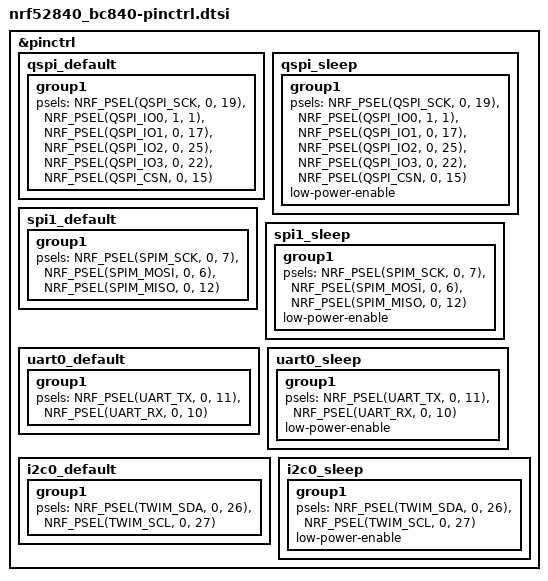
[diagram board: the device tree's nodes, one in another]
/*
 * Copyright (c) 2024 Nordic Semiconductor
 * SPDX-License-Identifier: Apache-2.0
 */

&pinctrl {
	/* QSPI pins for mx25l51245gz2i-08g (64MB) */
	qspi_default: qspi_default {
		group1 {
			psels = <NRF_PSEL(QSPI_SCK, 0, 19)>,
				<NRF_PSEL(QSPI_IO0, 1, 1)>,
				<NRF_PSEL(QSPI_IO1, 0, 17)>,
				<NRF_PSEL(QSPI_IO2, 0, 25)>,
				<NRF_PSEL(QSPI_IO3, 0, 22)>,
				<NRF_PSEL(QSPI_CSN, 0, 15)>;
		};
	};

	qspi_sleep: qspi_sleep {
		group1 {
			psels = <NRF_PSEL(QSPI_SCK, 0, 19)>,
				<NRF_PSEL(QSPI_IO0, 1, 1)>,
				<NRF_PSEL(QSPI_IO1, 0, 17)>,
				<NRF_PSEL(QSPI_IO2, 0, 25)>,
				<NRF_PSEL(QSPI_IO3, 0, 22)>,
				<NRF_PSEL(QSPI_CSN, 0, 15)>;
			low-power-enable;
		};
	};

	/* SPIFX pins for mx25l12845gz2i-08g (16MB) - also QSPI mode */
	/* Note: nRF52840 has only one hardware QSPI peripheral, so we use SPI in quad mode */
	spi1_default: spi1_default {
		group1 {
			psels = <NRF_PSEL(SPIM_SCK, 0, 7)>,
				<NRF_PSEL(SPIM_MOSI, 0, 6)>,
				<NRF_PSEL(SPIM_MISO, 0, 12)>;
		};
	};

	spi1_sleep: spi1_sleep {
		group1 {
			psels = <NRF_PSEL(SPIM_SCK, 0, 7)>,
				<NRF_PSEL(SPIM_MOSI, 0, 6)>,
				<NRF_PSEL(SPIM_MISO, 0, 12)>;
			low-power-enable;
		};
	};

	uart0_default: uart0_default {
		group1 {
			psels = <NRF_PSEL(UART_TX, 0, 11)>,
				<NRF_PSEL(UART_RX, 0, 10)>;
		};
	};

	uart0_sleep: uart0_sleep {
		group1 {
			psels = <NRF_PSEL(UART_TX, 0, 11)>,
				<NRF_PSEL(UART_RX, 0, 10)>;
			low-power-enable;
		};
	};

	i2c0_default: i2c0_default {
		group1 {
			psels = <NRF_PSEL(TWIM_SDA, 0, 26)>,
				<NRF_PSEL(TWIM_SCL, 0, 27)>;
		};
	};

	i2c0_sleep: i2c0_sleep {
		group1 {
			psels = <NRF_PSEL(TWIM_SDA, 0, 26)>,
				<NRF_PSEL(TWIM_SCL, 0, 27)>;
			low-power-enable;
		};
	};
};
